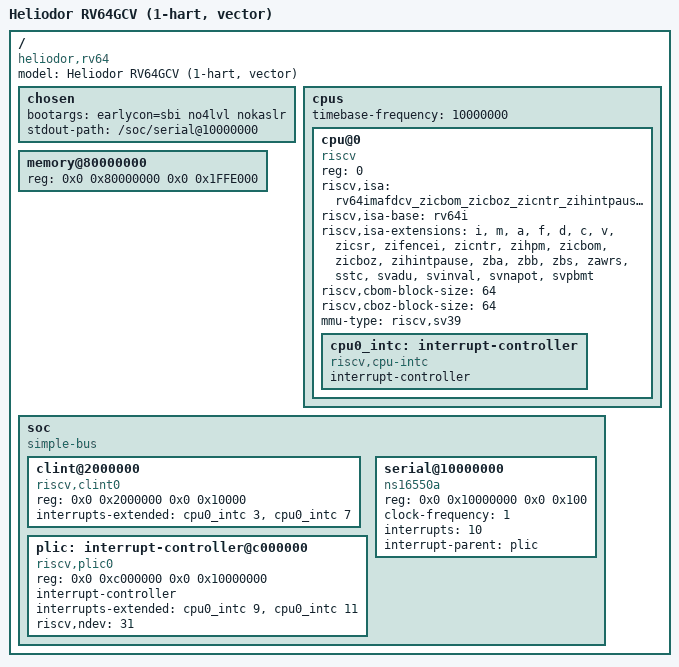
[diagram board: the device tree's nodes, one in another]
/dts-v1/;

/* Heliodor DTS for the Phase 12 V-enabled Linux 7.1 boot (1-hart).
 * Identical to heliodor_71.dts but advertises the vector extension: "v" is
 * added to riscv,isa and riscv,isa-extensions so the CONFIG_RISCV_ISA_V=y
 * kernel detects V, probes VLEN (a kernel-mode vsetvli), enables vector state
 * and lets the userspace /init run vector instructions on heliodor's VU.
 * memory = 32MB - 8KB; the top 8KB is reserved for the firmware
 * HART_SCRATCH_BASE (0x81FFE000) + mscratch (0x81FFF000). */

/ {
	#address-cells = <2>;
	#size-cells = <2>;
	compatible = "heliodor,rv64";
	model = "Heliodor RV64GCV (1-hart, vector)";

	chosen {
		bootargs = "earlycon=sbi no4lvl nokaslr";
		stdout-path = "/soc/serial@10000000";
	};

	cpus {
		#address-cells = <1>;
		#size-cells = <0>;
		timebase-frequency = <10000000>;

			cpu@0 {
				device_type = "cpu";
				compatible = "riscv";
				reg = <0>;
				riscv,isa = "rv64imafdcv_zicbom_zicboz_zicntr_zihintpause_zihpm_zba_zbb_zbs_zawrs_sstc_svadu_svinval_svnapot_svpbmt";
				riscv,isa-base = "rv64i";
				riscv,isa-extensions = "i", "m", "a", "f", "d", "c", "v",
				"zicsr", "zifencei", "zicntr", "zihpm",
				"zicbom", "zicboz", "zihintpause",
				"zba", "zbb", "zbs", "zawrs",
				"sstc", "svadu", "svinval", "svnapot", "svpbmt";
				riscv,cbom-block-size = <64>;
				riscv,cboz-block-size = <64>;
				mmu-type = "riscv,sv39";
				status = "okay";

				cpu0_intc: interrupt-controller {
					#interrupt-cells = <1>;
					compatible = "riscv,cpu-intc";
					interrupt-controller;
				};
			};
	};

	memory@80000000 {
		device_type = "memory";
		reg = <0x0 0x80000000 0x0 0x1FFE000>;
	};

	soc {
		#address-cells = <2>;
		#size-cells = <2>;
		compatible = "simple-bus";
		ranges;

		clint@2000000 {
			compatible = "riscv,clint0";
			reg = <0x0 0x2000000 0x0 0x10000>;
			interrupts-extended = <&cpu0_intc 3>, <&cpu0_intc 7>;
		};

		plic: interrupt-controller@c000000 {
			compatible = "riscv,plic0";
			reg = <0x0 0xc000000 0x0 0x10000000>;
			#interrupt-cells = <1>;
			interrupt-controller;
			interrupts-extended = <&cpu0_intc 9>, <&cpu0_intc 11>;
			riscv,ndev = <31>;
		};

		serial@10000000 {
			compatible = "ns16550a";
			reg = <0x0 0x10000000 0x0 0x100>;
			clock-frequency = <1>;
			interrupts = <10>;
			interrupt-parent = <&plic>;
		};
	};
};
